# PIC32MM0064GPL036 device description
Architecture: MIPS; Family: PIC32MM1324; Series: PIC32MM
Parameters: __INT_PRIO_LEVELS=7 (Number of interrupt priority levels), __INT_SUBPRIO_LEVELS=4 (Number of interrupt subpriority levels), __INT_NUM_SHADOW_SETS=1 (Number of interrupt shadow register sets), __SYS_DEF_FREQ=24000000 (System Clock Default Frequency), __PB_DEF_FREQ=24000000 (Peripheral Bus Default Clock Frequency), __REFCLK1_DEF_FREQ=24000000 (Reference Clock 1 Default Clock Frequency), __POSC_DEF_FREQ=8000000 (Primary Oscillator Input Default Frequency), __SOSC_DEF_FREQ=32768 (Secondary Oscillator Input Default Frequency), __PB_DEF_DIV=1 (Peripheral Bus Default Divider Value), __NUM_DMA_CHANNELS=0 (Number of DMA Channels), __NUM_CMP_CHANNELS=2 (Number of Comparator Channels), __DAC_RESOLUTION=5 (DAC resolution in bits), __NUM_ADC_PINS=14 (Number of ADC Pins)
Programming and debug interfaces: JTAG, SWD
Registers are 32-bit, read-write, no defined reset value unless marked. A register's access mark holds for its fields unless they carry their own. Offsets are from the block's base; lines under a group give offsets from that group; [hi:lo] are bit positions; {n}, {i} and the like mark numbered series; 'fields as' and 'values as' point back to an identical list; <NAME> marks a mode.

## Ordering variants
PIC32MM0064GPL036: VQFN36, up to 25 MHz, -40 to 85 C, 2 to 3.6 V
PIC32MM0064GPL036: UQFN40, up to 25 MHz, -40 to 85 C, 2 to 3.6 V

## Memory
base space: start 0 size 0x100000000, little endian
  0xff300000 emulation size 0x100000
  0xbf803b20 devid size 0x4
  0x1d000000 code size 0x10000
  0x1fc00000 bootconfig size 0x1700
  0x1fc01740 altconfig size 0x28
  0x0 kseg0_data_mem size 0x2000
  0x1f800000 periph0 size 0x8000
  0x1f808000 periph1 size 0x8000
  0x1FC41840 UDIDx size 0x14
config space: start 0x1fc017c0 size 0x28

## Peripheral instances (address, pins/pin function, parameters)
ADC at 0x1f800700 in periph0
CCP1 at CCP 0x1f800100 in periph0
  parameters: MCCP_PRESENT=1 (Extended PWM features)
CCP2
  parameters: MCCP_PRESENT=0 (Extended PWM features)
CCP3
  parameters: MCCP_PRESENT=0 (Extended PWM features)
CDAC1 at CDAC 0x1f800980 in periph0
CFG at 0x1f802300 in periph0
CLC1 at CLC 0x1f800a80 in periph0
CLC2
CMP at 0x1f800900 in periph0
CORE at 0x0
CRC at 0x1f800a00 in periph0
CRU at 0x1f802000 in periph0
FUSECONFIG at 0x1fc017c0 in config
GPIO at 0x1f802300 in periph0
HLVD at 0x1f802310 in periph0
INT at 0x1f802300 in periph0
NVM at 0x1f802380 in periph0
  parameters: PAGE_SIZE=2048, ROW_SIZE=256
RCON at 0x1f802000 in periph0
RTCC at 0x1f800000 in periph0
SPI1 at SPI 0x1f808080 in periph1
SPI2
TMR1 at 0x1f808000 in periph1
UART1 at UART 0x1f800600 in periph0
UART2
UDID at 0x1fc41840 in UDIDx
WDT at 0x1f803e80 in periph0

## Interrupts
0 CORE_TIMER
1 CORE_SOFTWARE_0
2 CORE_SOFTWARE_1
3 EXTERNAL_0
4 EXTERNAL_1
5 EXTERNAL_2
6 EXTERNAL_3
7 EXTERNAL_4
8 CHANGE_NOTICE_A — PORT A Change Notification
9 CHANGE_NOTICE_B — PORT B Change Notification
10 CHANGE_NOTICE_C — PORT C Change Notification
11 TIMER_1
12 COMPARATOR_1
13 COMPARATOR_2
14 RTCC — Real Time Clock Alarm
15 ADC — ADC Conversion Done
16 CRC
17 HLVD
18 CLC1 — Logic Cell 1
19 CLC2 — Logic Cell 2
20 SPI1_ERR — SPI 1 Error
21 SPI1_TX — SPI 1 Transmission
22 SPI1_RX — SPI 1 Reception
23 UART1_RX — UART 1 Reception
24 UART1_TX — UART 1 Transmission
25 UART1_ERR — UART 1 Error
29 CCP1 — CCP 1 Input Capture or Output Compare
30 CCT1 — CCP 1 Timer
31 CCP2 — CCP 2 Input Capture or Output Compare
32 CCT2 — CCP 2 Timer
33 CCP3 — CCP 3 Input Capture or Output Compare
34 CCT3 — CCP 3 Timer
37 SPI2_ERR — SPI 2 Error
38 SPI2_TX — SPI 2 Transmission
39 SPI2_RX — SPI 2 Reception
40 UART2_RX — UART 2 Reception
41 UART2_TX — UART 2 Transmission
42 UART2_ERR — UART 2 Error
46 NVM — NVM Program or Erase Complete
47 PERFORMANCE_COUNTER — Core Performance Counter

## CDAC
Instances: CDAC 0x1f800980 in periph0
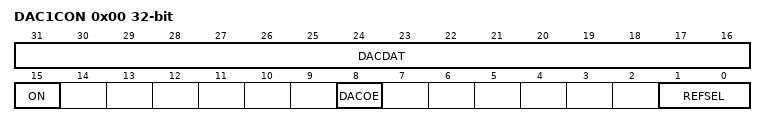
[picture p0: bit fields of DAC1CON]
0x00 DAC1CON — CDAC Control Register
  [31:16] DACDAT — Data Input Register Bits for the CDAC
  [15] ON — CDAC Enable
    0=The CDAC is Disabled; 1=The CDAC is Enabled
  [8] DACOE — CDAC Output Enable
    0=Output is Disabled; drive to pin is floating; 1=Output is Enabled; CDAC voltage is connected to the pin
  [1:0] REFSEL — Reference Source Select
    0=No reference is selected (output is AVSS); 1=Reference voltage is the CVREF+ input pin voltage; 2=No reference is selected (output is AVSS); 3=Reference voltage is AVDD

## Notices in the file
Copyright (c) 2019 Microchip Technology Inc.
SPDX-License-Identifier: Apache-2.0
Licensed under the Apache License, Version 2.0 (the "License");
you may not use this file except in compliance with the License.
You may obtain a copy of the License at
http://www.apache.org/licenses/LICENSE-2.0
Unless required by applicable law or agreed to in writing, software
distributed under the License is distributed on an "AS IS" BASIS,
WITHOUT WARRANTIES OR CONDITIONS OF ANY KIND, either express or implied.
See the License for the specific language governing permissions and
limitations under the License.
